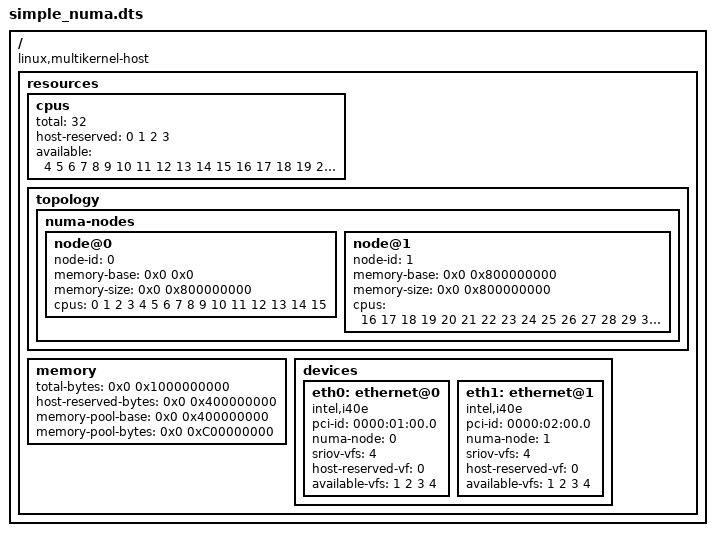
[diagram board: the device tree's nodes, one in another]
/*
 * Simple NUMA Baseline Example
 *
 * Baseline defines hardware resources with basic NUMA configuration.
 * Usage: kerf init --input=simple_numa.dts --apply
 */

/multikernel-v1/;

/ {
    compatible = "linux,multikernel-host";

    resources {
        cpus {
            total = <32>;
            host-reserved = <0 1 2 3>;
            available = <4 5 6 7 8 9 10 11 12 13 14 15 16 17 18 19 
                        20 21 22 23 24 25 26 27 28 29 30 31>;
        };
        
        topology {
            numa-nodes {
                node@0 {
                    node-id = <0>;
                    memory-base = <0x0 0x0>;
                    memory-size = <0x0 0x800000000>;  // 16GB
                    cpus = <0 1 2 3 4 5 6 7 8 9 10 11 12 13 14 15>;
                };
                
                node@1 {
                    node-id = <1>;
                    memory-base = <0x0 0x800000000>;
                    memory-size = <0x0 0x800000000>;  // 16GB
                    cpus = <16 17 18 19 20 21 22 23 24 25 26 27 28 29 30 31>;
                };
            };
        };
        
        memory {
            total-bytes = <0x0 0x1000000000>;      // 64GB
            host-reserved-bytes = <0x0 0x400000000>; // 16GB
            memory-pool-base = <0x0 0x400000000>;
            memory-pool-bytes = <0x0 0xC00000000>;  // 48GB
        };
        
        devices {
            eth0: ethernet@0 {
                compatible = "intel,i40e";
                pci-id = "0000:01:00.0";
                numa-node = <0>;
                sriov-vfs = <4>;
                host-reserved-vf = <0>;
                available-vfs = <1 2 3 4>;
            };
            
            eth1: ethernet@1 {
                compatible = "intel,i40e";
                pci-id = "0000:02:00.0";
                numa-node = <1>;
                sriov-vfs = <4>;
                host-reserved-vf = <0>;
                available-vfs = <1 2 3 4>;
            };
        };
    };
};
